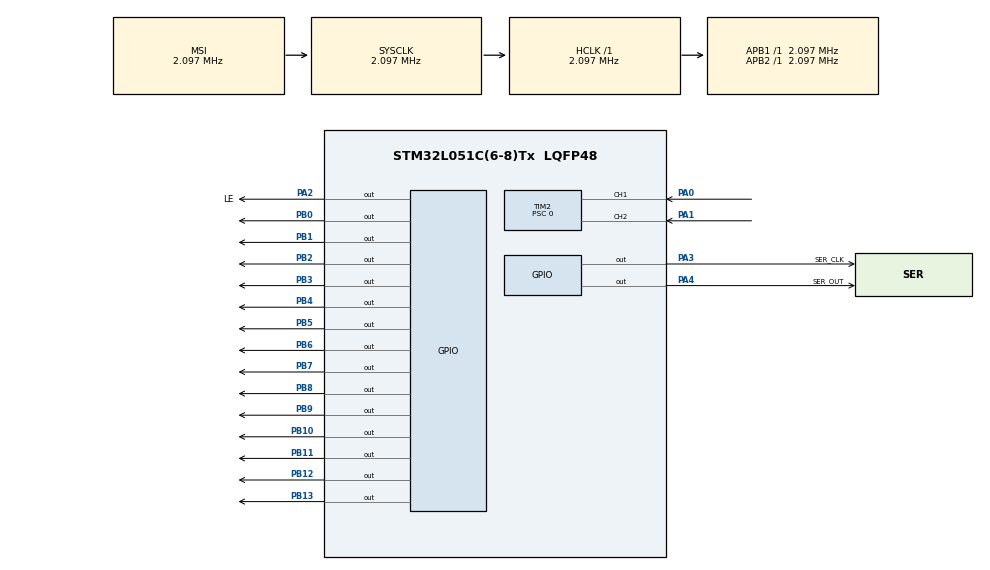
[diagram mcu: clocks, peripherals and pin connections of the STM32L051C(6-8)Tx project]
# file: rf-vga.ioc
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Mcu.Family=STM32L0
Mcu.Name=STM32L051C(6-8)Tx
Mcu.Package=LQFP48
PA0.Signal=S_TIM2_CH1
PA1.Signal=S_TIM2_CH2
PA13.Mode=Serial_Wire
PA13.Signal=SYS_SWDIO
PA14.Mode=Serial_Wire
PA14.Signal=SYS_SWCLK
PA2.GPIO_Label=LE
PA2.Signal=GPIO_Output
PA3.GPIO_Label=SER_CLK
PA3.Signal=GPIO_Output
PA4.GPIO_Label=SER_OUT
PA4.Signal=GPIO_Output
PB0.Signal=GPIO_Output
PB1.Signal=GPIO_Output
PB10.Signal=GPIO_Output
PB11.Signal=GPIO_Output
PB12.Signal=GPIO_Output
PB13.Signal=GPIO_Output
PB2.Signal=GPIO_Output
PB3.Signal=GPIO_Output
PB4.Signal=GPIO_Output
PB5.Signal=GPIO_Output
PB6.Signal=GPIO_Output
PB7.Signal=GPIO_Output
PB8.Signal=GPIO_Output
PB9.Signal=GPIO_Output
ProjectManager.HeapSize=0x200
ProjectManager.StackSize=0x400
ProjectManager.TargetToolchain=STM32CubeIDE
RCC.AHBFreq_Value=2097000
RCC.APB1Freq_Value=2097000
RCC.APB1TimFreq_Value=2097000
RCC.APB2Freq_Value=2097000
RCC.APB2TimFreq_Value=2097000
RCC.HSE_VALUE=8000000
RCC.HSI16_VALUE=16000000
RCC.HSI_VALUE=16000000
RCC.LSE_VALUE=32768
RCC.MSI_VALUE=2097000
RCC.SYSCLKFreq_VALUE=2097000
RCC.VCOOutputFreq_Value=48000000
SH.S_TIM2_CH1.0=TIM2_CH1,Encoder_Interface
SH.S_TIM2_CH2.0=TIM2_CH2,Encoder_Interface
TIM2.AutoReloadPreload=TIM_AUTORELOAD_PRELOAD_ENABLE
TIM2.ClockDivision=TIM_CLOCKDIVISION_DIV1
TIM2.CounterMode=TIM_COUNTERMODE_UP
TIM2.EncoderMode=TIM_ENCODERMODE_TI1
TIM2.IC1Filter=10
TIM2.IC1Polarity=TIM_ICPOLARITY_RISING
TIM2.IC1Prescaler=TIM_ICPSC_DIV1
TIM2.IC1Selection=TIM_ICSELECTION_DIRECTTI
TIM2.IC2Filter=10
TIM2.IC2Polarity=TIM_ICPOLARITY_RISING
TIM2.IC2Prescaler=TIM_ICPSC_DIV1
TIM2.IC2Selection=TIM_ICSELECTION_DIRECTTI
TIM2.Period=65535
TIM2.Prescaler=0
TIM2.TIM_MasterOutputTrigger=TIM_TRGO_RESET
TIM2.TIM_MasterSlaveMode=TIM_MASTERSLAVEMODE_DISABLE
TIM21.AutoReloadPreload=TIM_AUTORELOAD_PRELOAD_ENABLE
TIM21.ClockDivision=TIM_CLOCKDIVISION_DIV1
TIM21.CounterMode=TIM_COUNTERMODE_UP
TIM21.Period=0xffff
TIM21.Prescaler=0
TIM21.TIM_MasterOutputTrigger=TIM_TRGO_RESET
TIM21.TIM_MasterSlaveMode=TIM_MASTERSLAVEMODE_DISABLE
VP_TIM21_VS_ClockSourceINT.Mode=Internal
board=custom

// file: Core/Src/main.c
/* USER CODE BEGIN Header */
/**
  ******************************************************************************
  * @file           : main.c
  * @brief          : Main program body
  ******************************************************************************
  * @attention
  *
  * <h2><center>&copy; Copyright (c) 2021 STMicroelectronics.
  * All rights reserved.</center></h2>
  *
  * This software component is licensed by ST under BSD 3-Clause license,
  * the "License"; You may not use this file except in compliance with the
  * License. You may obtain a copy of the License at:
  *                        opensource.org/licenses/BSD-3-Clause
  *
  ******************************************************************************
  */
/* USER CODE END Header */
#include "main.h"

/* USER CODE BEGIN Includes */
#include "rf-vga.h"
/* USER CODE END Includes */

TIM_HandleTypeDef htim2;
TIM_HandleTypeDef htim21;

void SystemClock_Config(void);
static void MX_GPIO_Init(void);
static void MX_TIM2_Init(void);
static void MX_TIM21_Init(void);

int main(void)
{

  /* MCU Configuration--------------------------------------------------------*/

  /* Reset of all peripherals, Initializes the Flash interface and the Systick. */
  HAL_Init();

  /* Configure the system clock */
  SystemClock_Config();

  /* Initialize all configured peripherals */
  MX_GPIO_Init();
  MX_TIM2_Init();
  MX_TIM21_Init();
  /* USER CODE BEGIN 2 */
  HAL_TIM_Encoder_Start(&htim2, TIM_CHANNEL_ALL);
  HAL_TIM_Base_Start_IT(&htim21);
  /* USER CODE END 2 */

  /* Infinite loop */
  while (1)
  {
	main_loop();
  }
}

void SystemClock_Config(void)
{
  RCC_OscInitTypeDef RCC_OscInitStruct = {0};
  RCC_ClkInitTypeDef RCC_ClkInitStruct = {0};

  /** Configure the main internal regulator output voltage
  */
  __HAL_PWR_VOLTAGESCALING_CONFIG(PWR_REGULATOR_VOLTAGE_SCALE1);
  /** Initializes the RCC Oscillators according to the specified parameters
  * in the RCC_OscInitTypeDef structure.
  */
  RCC_OscInitStruct.OscillatorType = RCC_OSCILLATORTYPE_MSI;
  RCC_OscInitStruct.MSIState = RCC_MSI_ON;
  RCC_OscInitStruct.MSICalibrationValue = 0;
  RCC_OscInitStruct.MSIClockRange = RCC_MSIRANGE_5;
  RCC_OscInitStruct.PLL.PLLState = RCC_PLL_NONE;
  if (HAL_RCC_OscConfig(&RCC_OscInitStruct) != HAL_OK)
  {
    Error_Handler();
  }
  /** Initializes the CPU, AHB and APB buses clocks
  */
  RCC_ClkInitStruct.ClockType = RCC_CLOCKTYPE_HCLK|RCC_CLOCKTYPE_SYSCLK
                              |RCC_CLOCKTYPE_PCLK1|RCC_CLOCKTYPE_PCLK2;
  RCC_ClkInitStruct.SYSCLKSource = RCC_SYSCLKSOURCE_MSI;
  RCC_ClkInitStruct.AHBCLKDivider = RCC_SYSCLK_DIV1;
  RCC_ClkInitStruct.APB1CLKDivider = RCC_HCLK_DIV1;
  RCC_ClkInitStruct.APB2CLKDivider = RCC_HCLK_DIV1;

  if (HAL_RCC_ClockConfig(&RCC_ClkInitStruct, FLASH_LATENCY_0) != HAL_OK)
  {
    Error_Handler();
  }
}

static void MX_TIM2_Init(void)
{

  TIM_Encoder_InitTypeDef sConfig = {0};
  TIM_MasterConfigTypeDef sMasterConfig = {0};

  htim2.Instance = TIM2;
  htim2.Init.Prescaler = 0;
  htim2.Init.CounterMode = TIM_COUNTERMODE_UP;
  htim2.Init.Period = 65535;
  htim2.Init.ClockDivision = TIM_CLOCKDIVISION_DIV1;
  htim2.Init.AutoReloadPreload = TIM_AUTORELOAD_PRELOAD_ENABLE;
  sConfig.EncoderMode = TIM_ENCODERMODE_TI1;
  sConfig.IC1Polarity = TIM_ICPOLARITY_RISING;
  sConfig.IC1Selection = TIM_ICSELECTION_DIRECTTI;
  sConfig.IC1Prescaler = TIM_ICPSC_DIV1;
  sConfig.IC1Filter = 10;
  sConfig.IC2Polarity = TIM_ICPOLARITY_RISING;
  sConfig.IC2Selection = TIM_ICSELECTION_DIRECTTI;
  sConfig.IC2Prescaler = TIM_ICPSC_DIV1;
  sConfig.IC2Filter = 10;
  if (HAL_TIM_Encoder_Init(&htim2, &sConfig) != HAL_OK)
  {
    Error_Handler();
  }
  sMasterConfig.MasterOutputTrigger = TIM_TRGO_RESET;
  sMasterConfig.MasterSlaveMode = TIM_MASTERSLAVEMODE_DISABLE;
  if (HAL_TIMEx_MasterConfigSynchronization(&htim2, &sMasterConfig) != HAL_OK)
  {
    Error_Handler();
  }

}

static void MX_TIM21_Init(void)
{

  TIM_ClockConfigTypeDef sClockSourceConfig = {0};
  TIM_MasterConfigTypeDef sMasterConfig = {0};

  htim21.Instance = TIM21;
  htim21.Init.Prescaler = 0;
  htim21.Init.CounterMode = TIM_COUNTERMODE_UP;
  htim21.Init.Period = 0xffff;
  htim21.Init.ClockDivision = TIM_CLOCKDIVISION_DIV1;
  htim21.Init.AutoReloadPreload = TIM_AUTORELOAD_PRELOAD_ENABLE;
  if (HAL_TIM_Base_Init(&htim21) != HAL_OK)
  {
    Error_Handler();
  }
  sClockSourceConfig.ClockSource = TIM_CLOCKSOURCE_INTERNAL;
  if (HAL_TIM_ConfigClockSource(&htim21, &sClockSourceConfig) != HAL_OK)
  {
    Error_Handler();
  }
  sMasterConfig.MasterOutputTrigger = TIM_TRGO_RESET;
  sMasterConfig.MasterSlaveMode = TIM_MASTERSLAVEMODE_DISABLE;
  if (HAL_TIMEx_MasterConfigSynchronization(&htim21, &sMasterConfig) != HAL_OK)
  {
    Error_Handler();
  }

}

static void MX_GPIO_Init(void)
{
  GPIO_InitTypeDef GPIO_InitStruct = {0};

  /* GPIO Ports Clock Enable */
  __HAL_RCC_GPIOA_CLK_ENABLE();
  __HAL_RCC_GPIOB_CLK_ENABLE();

  /*Configure GPIO pin Output Level */
  HAL_GPIO_WritePin(GPIOA, LE_Pin|SER_CLK_Pin|SER_OUT_Pin, GPIO_PIN_RESET);

  /*Configure GPIO pin Output Level */
  HAL_GPIO_WritePin(GPIOB, GPIO_PIN_0|GPIO_PIN_1|GPIO_PIN_2|GPIO_PIN_10
                          |GPIO_PIN_11|GPIO_PIN_12|GPIO_PIN_13|GPIO_PIN_3
                          |GPIO_PIN_4|GPIO_PIN_5|GPIO_PIN_6|GPIO_PIN_7
                          |GPIO_PIN_8|GPIO_PIN_9, GPIO_PIN_RESET);

  /*Configure GPIO pins : LE_Pin SER_CLK_Pin SER_OUT_Pin */
  GPIO_InitStruct.Pin = LE_Pin|SER_CLK_Pin|SER_OUT_Pin;
  GPIO_InitStruct.Mode = GPIO_MODE_OUTPUT_PP;
  GPIO_InitStruct.Pull = GPIO_NOPULL;
  GPIO_InitStruct.Speed = GPIO_SPEED_FREQ_LOW;
  HAL_GPIO_Init(GPIOA, &GPIO_InitStruct);

  /*Configure GPIO pins : PB0 PB1 PB2 PB10
                           PB11 PB12 PB13 PB3
                           PB4 PB5 PB6 PB7
                           PB8 PB9 */
  GPIO_InitStruct.Pin = GPIO_PIN_0|GPIO_PIN_1|GPIO_PIN_2|GPIO_PIN_10
                          |GPIO_PIN_11|GPIO_PIN_12|GPIO_PIN_13|GPIO_PIN_3
                          |GPIO_PIN_4|GPIO_PIN_5|GPIO_PIN_6|GPIO_PIN_7
                          |GPIO_PIN_8|GPIO_PIN_9;
  GPIO_InitStruct.Mode = GPIO_MODE_OUTPUT_PP;
  GPIO_InitStruct.Pull = GPIO_NOPULL;
  GPIO_InitStruct.Speed = GPIO_SPEED_FREQ_LOW;
  HAL_GPIO_Init(GPIOB, &GPIO_InitStruct);

}

/* USER CODE BEGIN 4 */

void delay_us(uint16_t us) {
  uint16_t start = TIM21->CNT;
  while((TIM21->CNT - start) < us); // rebase, then compare
}

/* USER CODE END 4 */

void Error_Handler(void)
{
  __disable_irq();
  while (1)
  {
  }
}
